# MSPM0G351X register map
Vendor: Texas Instruments; File version: This preliminary header file does not have a version number - build date: 2024-07-25 04:30:36
CPU: CM0 r0p1, little endian, MPU, no FPU, 3 interrupt priority bits
Registers are 32-bit, read-write, reset 0x0 unless marked. A register's access mark holds for its fields unless they carry their own. Offsets are from the block's base; [hi:lo] are bit positions; lines under a group give offsets from that group; {n}, {i} and the like mark numbered series; 'fields as' and 'values as' point back to an identical list.

## CPUSS — CPUSSMMR
Base 0x40400000
0x10E0 CPUSS_EVT_MODE ro — Event Mode
  [1:0] INT_CFG — Event line mode select
    0=DISABLE (The interrupt or event line is disabled.); 1=SOFTWARE (Event handled by software. Software must clear the associated RIS flag.); 2=HARDWARE (Event handled by hardware. The hardware (another module) clears automatically the associated RIS flag.)
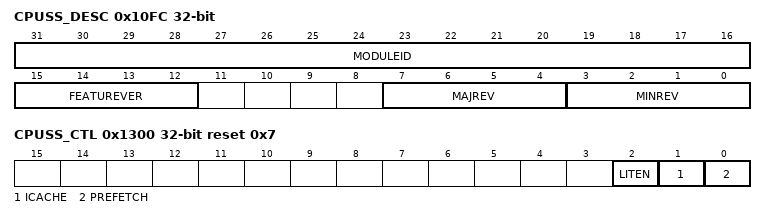
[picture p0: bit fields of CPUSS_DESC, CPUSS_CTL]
0x10FC CPUSS_DESC ro — Module Description
  [31:16] MODULEID — Module identification contains a unique peripheral identification number. The assignments are maintained in a central database for all of the platform modules to ensure uniqueness.
  [15:12] FEATUREVER — Feature Set for the module *instance*
  [7:4] MAJREV — Major rev of the IP
  [3:0] MINREV — Minor rev of the IP
{0x1100+0x2C*i} CPUSS_CPU_INT_GROUP0[{i}] (i=0..0) group
  0x00 CPUSS_CPU_INT_GROUP0_IIDX ro — Interrupt index
    [7:0] STAT — Interrupt index status
      0=NO_INTR (No pending interrupt); {v}=INT{v-1} (Interrupt {v-1}) (v=1..8)
  0x08 CPUSS_CPU_INT_GROUP0_IMASK ro reset 0xFF — Interrupt mask
    [7:0] INT — Masks the corresponding interrupt
      1=Interrupt 0; 2=Interrupt 1; 4=Interrupt 2; 8=Interrupt 3; 16=Interrupt 4; 32=Interrupt 5; 64=Interrupt 6; 128=Interrupt 7
  0x10 CPUSS_CPU_INT_GROUP0_RIS ro — Raw interrupt status
    [7:0] INT — Raw interrupt status for INT
      values as CPUSS_CPU_INT_GROUP0[0].CPUSS_CPU_INT_GROUP0_IMASK.INT
  0x18 CPUSS_CPU_INT_GROUP0_MIS ro — Masked interrupt status
    [7:0] INT — Masked interrupt status for INT0
      values as CPUSS_CPU_INT_GROUP0[0].CPUSS_CPU_INT_GROUP0_IMASK.INT
  0x20 CPUSS_CPU_INT_GROUP0_ISET wo — Interrupt set
    [7:0] INT — Sets INT in RIS register
      values as CPUSS_CPU_INT_GROUP0[0].CPUSS_CPU_INT_GROUP0_IMASK.INT
  0x28 CPUSS_CPU_INT_GROUP0_ICLR wo — Interrupt clear
    [7:0] INT — Clears INT in RIS register
      values as CPUSS_CPU_INT_GROUP0[0].CPUSS_CPU_INT_GROUP0_IMASK.INT
{0x1130+0x2C*i} CPUSS_CPU_INT_GROUP1[{i}] (i=0..0) group
  0x00 CPUSS_CPU_INT_GROUP1_IIDX ro — Interrupt index
    fields as CPUSS_CPU_INT_GROUP0[0].CPUSS_CPU_INT_GROUP0_IIDX
  0x08 CPUSS_CPU_INT_GROUP1_IMASK ro reset 0xFF — Interrupt mask
    fields as CPUSS_CPU_INT_GROUP0[0].CPUSS_CPU_INT_GROUP0_IMASK
  0x10 CPUSS_CPU_INT_GROUP1_RIS ro — Raw interrupt status
    fields as CPUSS_CPU_INT_GROUP0[0].CPUSS_CPU_INT_GROUP0_RIS
  0x18 CPUSS_CPU_INT_GROUP1_MIS ro — Masked interrupt status
    fields as CPUSS_CPU_INT_GROUP0[0].CPUSS_CPU_INT_GROUP0_MIS
  0x20 CPUSS_CPU_INT_GROUP1_ISET wo — Interrupt set
    fields as CPUSS_CPU_INT_GROUP0[0].CPUSS_CPU_INT_GROUP0_ISET
  0x28 CPUSS_CPU_INT_GROUP1_ICLR wo — Interrupt clear
    fields as CPUSS_CPU_INT_GROUP0[0].CPUSS_CPU_INT_GROUP0_ICLR
0x1300 CPUSS_CTL reset 0x7 — Prefetch/Cache control
  [2] LITEN — Literal caching and prefetch enable. This bit is a subset of ICACHE/PREFETCH bit i.e. literal caching or literal prefetching will only happen if ICACHE or PREFETCH bits have been set respectively When enabled, the cache and prefetcher structures inside CPUSS will cache and prefetch literals When disabled, the cache and prefetcher structures inside CPUSS will not cache and prefetch literals
    0=DISABLE (Literal caching disabled); 1=ENABLE (Literal caching enabled)
  [1] ICACHE — Used to enable/disable Instruction caching on flash access.
    0=DISABLE (Disable instruction caching.); 1=ENABLE (Enable instruction caching.)
  [0] PREFETCH — Used to enable/disable instruction prefetch to Flash.
    0=DISABLE (Disable instruction prefetch.); 1=ENABLE (Enable instruction prefetch.)
